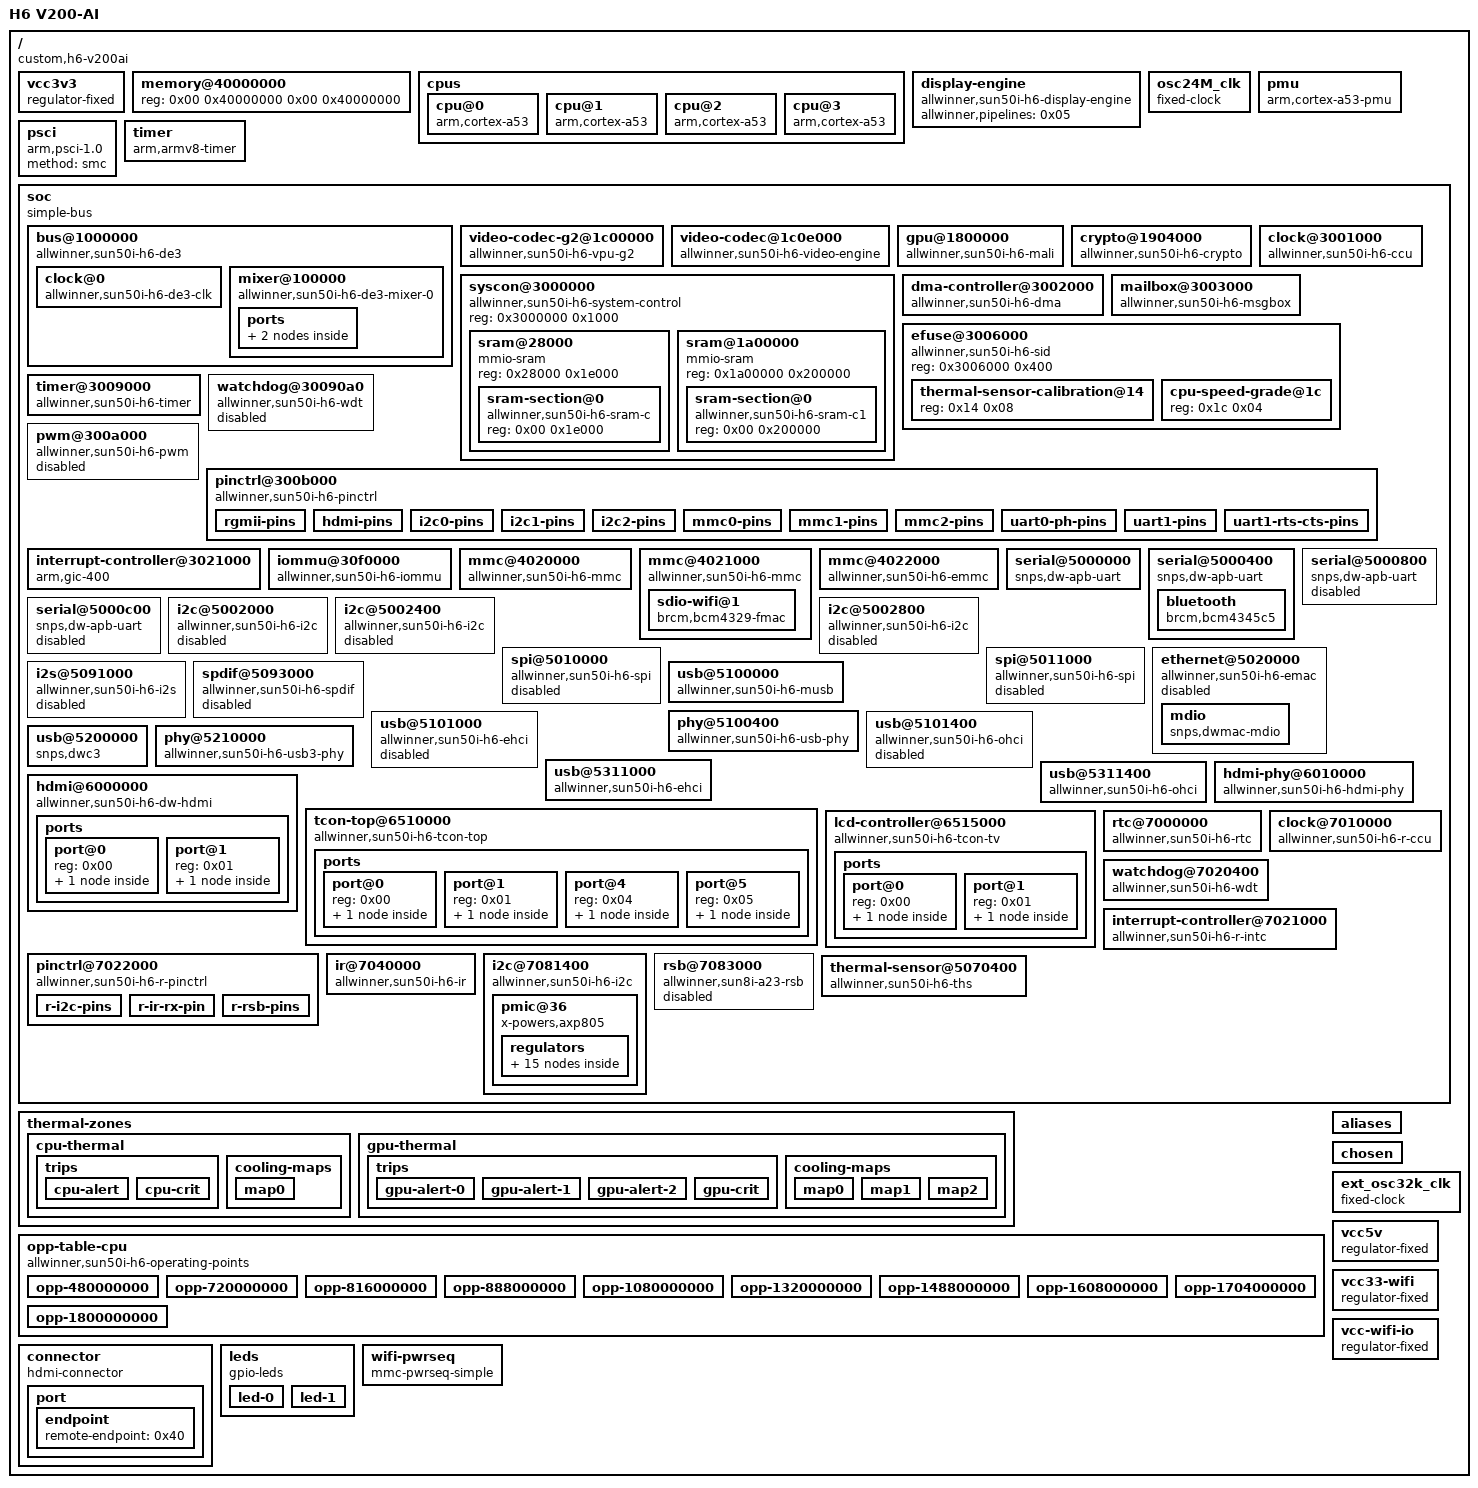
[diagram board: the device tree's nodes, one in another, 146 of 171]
/dts-v1/;

/ {
	interrupt-parent = <0x01>;
	#address-cells = <0x01>;
	#size-cells = <0x01>;
	model = "H6 V200-AI";
	compatible = "custom,h6-v200ai", "allwinner,sun50i-h6";

	vcc3v3 {
		compatible = "regulator-fixed";
		regulator-name = "vcc-3v3";
		regulator-min-microvolt = <0x325aa0>;
		regulator-max-microvolt = <0x325aa0>;
		regulator-always-on;
		phandle = <0x99>;
	};

	memory@40000000 {
		device_type = "memory";
		reg = <0x00 0x40000000 0x00 0x40000000>;
	};

	cpus {
		#address-cells = <0x01>;
		#size-cells = <0x00>;

		cpu@0 {
			compatible = "arm,cortex-a53";
			device_type = "cpu";
			reg = <0x00>;
			enable-method = "psci";
			clocks = <0x02 0x15>;
			clock-latency-ns = <0x3b9b0>;
			#cooling-cells = <0x02>;
			operating-points-v2 = <0x03>;
			cpu-supply = <0x04>;
			phandle = <0x06>;
		};

		cpu@1 {
			compatible = "arm,cortex-a53";
			device_type = "cpu";
			reg = <0x01>;
			enable-method = "psci";
			clocks = <0x02 0x15>;
			clock-latency-ns = <0x3b9b0>;
			#cooling-cells = <0x02>;
			operating-points-v2 = <0x03>;
			phandle = <0x07>;
		};

		cpu@2 {
			compatible = "arm,cortex-a53";
			device_type = "cpu";
			reg = <0x02>;
			enable-method = "psci";
			clocks = <0x02 0x15>;
			clock-latency-ns = <0x3b9b0>;
			#cooling-cells = <0x02>;
			operating-points-v2 = <0x03>;
			phandle = <0x08>;
		};

		cpu@3 {
			compatible = "arm,cortex-a53";
			device_type = "cpu";
			reg = <0x03>;
			enable-method = "psci";
			clocks = <0x02 0x15>;
			clock-latency-ns = <0x3b9b0>;
			#cooling-cells = <0x02>;
			operating-points-v2 = <0x03>;
			phandle = <0x09>;
		};
	};

	display-engine {
		compatible = "allwinner,sun50i-h6-display-engine";
		allwinner,pipelines = <0x05>;
		status = "okay";
	};

	osc24M_clk {
		#clock-cells = <0x00>;
		compatible = "fixed-clock";
		clock-frequency = <0x16e3600>;
		clock-output-names = "osc24M";
		phandle = <0x10>;
	};

	pmu {
		compatible = "arm,cortex-a53-pmu";
		interrupts = <0x00 0x8c 0x04 0x00 0x8d 0x04 0x00 0x8e 0x04 0x00 0x8f 0x04>;
		interrupt-affinity = <0x06 0x07 0x08 0x09>;
	};

	psci {
		compatible = "arm,psci-1.0";
		method = "smc";
	};

	timer {
		compatible = "arm,armv8-timer";
		arm,no-tick-in-suspend;
		interrupts = <0x01 0x0d 0xf04 0x01 0x0e 0xf04 0x01 0x0b 0xf04 0x01 0x0a 0xf04>;
	};

	soc {
		compatible = "simple-bus";
		#address-cells = <0x01>;
		#size-cells = <0x01>;
		ranges;

		bus@1000000 {
			compatible = "allwinner,sun50i-h6-de3", "allwinner,sun50i-a64-de2";
			reg = <0x1000000 0x400000>;
			allwinner,sram = <0x0a 0x01>;
			#address-cells = <0x01>;
			#size-cells = <0x01>;
			ranges = <0x00 0x1000000 0x400000>;

			clock@0 {
				compatible = "allwinner,sun50i-h6-de3-clk";
				reg = <0x00 0x10000>;
				clocks = <0x02 0x1e 0x02 0x1d>;
				clock-names = "bus", "mod";
				resets = <0x02 0x01>;
				#clock-cells = <0x01>;
				#reset-cells = <0x01>;
				phandle = <0x0b>;
			};

			mixer@100000 {
				compatible = "allwinner,sun50i-h6-de3-mixer-0";
				reg = <0x100000 0x100000>;
				clocks = <0x0b 0x00 0x0b 0x06>;
				clock-names = "bus", "mod";
				resets = <0x0b 0x00>;
				iommus = <0x0c 0x00>;
				phandle = <0x05>;

				ports {
					#address-cells = <0x01>;
					#size-cells = <0x00>;

					port@1 {
						reg = <0x01>;

						endpoint {
							remote-endpoint = <0x0d>;
							phandle = <0x2c>;
						};
					};
				};
			};
		};

		video-codec-g2@1c00000 {
			compatible = "allwinner,sun50i-h6-vpu-g2";
			reg = <0x1c00000 0x1000>;
			interrupts = <0x00 0x5a 0x04>;
			clocks = <0x02 0x2a 0x02 0x29>;
			clock-names = "bus", "mod";
			resets = <0x02 0x07>;
			iommus = <0x0c 0x05>;
		};

		video-codec@1c0e000 {
			compatible = "allwinner,sun50i-h6-video-engine";
			reg = <0x1c0e000 0x2000>;
			clocks = <0x02 0x26 0x02 0x25 0x02 0x36>;
			clock-names = "ahb", "mod", "ram";
			resets = <0x02 0x05>;
			interrupts = <0x00 0x59 0x04>;
			allwinner,sram = <0x0e 0x01>;
			iommus = <0x0c 0x03>;
		};

		gpu@1800000 {
			compatible = "allwinner,sun50i-h6-mali", "arm,mali-t720";
			reg = <0x1800000 0x4000>;
			interrupts = <0x00 0x54 0x04 0x00 0x55 0x04 0x00 0x53 0x04>;
			interrupt-names = "job", "mmu", "gpu";
			clocks = <0x02 0x21 0x02 0x22>;
			clock-names = "core", "bus";
			resets = <0x02 0x03>;
			#cooling-cells = <0x02>;
			status = "okay";
			mali-supply = <0x0f>;
			phandle = <0x3c>;
		};

		crypto@1904000 {
			compatible = "allwinner,sun50i-h6-crypto";
			reg = <0x1904000 0x1000>;
			interrupts = <0x00 0x57 0x04>;
			clocks = <0x02 0x24 0x02 0x23 0x02 0x37>;
			clock-names = "bus", "mod", "ram";
			resets = <0x02 0x04>;
		};

		syscon@3000000 {
			compatible = "allwinner,sun50i-h6-system-control", "allwinner,sun50i-a64-system-control";
			reg = <0x3000000 0x1000>;
			#address-cells = <0x01>;
			#size-cells = <0x01>;
			ranges;
			phandle = <0x24>;

			sram@28000 {
				compatible = "mmio-sram";
				reg = <0x28000 0x1e000>;
				#address-cells = <0x01>;
				#size-cells = <0x01>;
				ranges = <0x00 0x28000 0x1e000>;

				sram-section@0 {
					compatible = "allwinner,sun50i-h6-sram-c", "allwinner,sun50i-a64-sram-c";
					reg = <0x00 0x1e000>;
					phandle = <0x0a>;
				};
			};

			sram@1a00000 {
				compatible = "mmio-sram";
				reg = <0x1a00000 0x200000>;
				#address-cells = <0x01>;
				#size-cells = <0x01>;
				ranges = <0x00 0x1a00000 0x200000>;

				sram-section@0 {
					compatible = "allwinner,sun50i-h6-sram-c1", "allwinner,sun4i-a10-sram-c1";
					reg = <0x00 0x200000>;
					phandle = <0x0e>;
				};
			};
		};

		clock@3001000 {
			compatible = "allwinner,sun50i-h6-ccu";
			reg = <0x3001000 0x1000>;
			clocks = <0x10 0x11 0x00 0x11 0x02>;
			clock-names = "hosc", "losc", "iosc";
			#clock-cells = <0x01>;
			#reset-cells = <0x01>;
			phandle = <0x02>;
		};

		dma-controller@3002000 {
			compatible = "allwinner,sun50i-h6-dma";
			reg = <0x3002000 0x1000>;
			interrupts = <0x00 0x2b 0x04>;
			clocks = <0x02 0x2b 0x02 0x35>;
			clock-names = "bus", "mbus";
			dma-channels = <0x10>;
			dma-requests = <0x2e>;
			resets = <0x02 0x08>;
			#dma-cells = <0x01>;
			phandle = <0x23>;
		};

		mailbox@3003000 {
			compatible = "allwinner,sun50i-h6-msgbox", "allwinner,sun6i-a31-msgbox";
			reg = <0x3003000 0x1000>;
			clocks = <0x02 0x2c>;
			resets = <0x02 0x09>;
			interrupts = <0x00 0x2c 0x04>;
			#mbox-cells = <0x01>;
		};

		efuse@3006000 {
			compatible = "allwinner,sun50i-h6-sid";
			reg = <0x3006000 0x400>;
			#address-cells = <0x01>;
			#size-cells = <0x01>;

			thermal-sensor-calibration@14 {
				reg = <0x14 0x08>;
				phandle = <0x38>;
			};

			cpu-speed-grade@1c {
				reg = <0x1c 0x04>;
				phandle = <0x3f>;
			};
		};

		timer@3009000 {
			compatible = "allwinner,sun50i-h6-timer", "allwinner,sun8i-a23-timer";
			reg = <0x3009000 0xa0>;
			interrupts = <0x00 0x30 0x04 0x00 0x31 0x04>;
			clocks = <0x10>;
		};

		watchdog@30090a0 {
			compatible = "allwinner,sun50i-h6-wdt", "allwinner,sun6i-a31-wdt";
			reg = <0x30090a0 0x20>;
			interrupts = <0x00 0x32 0x04>;
			clocks = <0x10>;
			status = "disabled";
		};

		pwm@300a000 {
			compatible = "allwinner,sun50i-h6-pwm";
			reg = <0x300a000 0x400>;
			clocks = <0x10 0x02 0x32>;
			clock-names = "mod", "bus";
			resets = <0x02 0x0e>;
			#pwm-cells = <0x03>;
			status = "disabled";
		};

		pinctrl@300b000 {
			compatible = "allwinner,sun50i-h6-pinctrl";
			reg = <0x300b000 0x400>;
			interrupt-parent = <0x12>;
			interrupts = <0x00 0x33 0x04 0x00 0x35 0x04 0x00 0x36 0x04 0x00 0x3b 0x04>;
			clocks = <0x02 0x1a 0x10 0x11 0x00>;
			clock-names = "apb", "hosc", "losc";
			gpio-controller;
			#gpio-cells = <0x03>;
			interrupt-controller;
			#interrupt-cells = <0x03>;
			phandle = <0x17>;

			rgmii-pins {
				pins = "PD0", "PD1", "PD2", "PD3", "PD4", "PD5", "PD7", "PD8", "PD9", "PD10", "PD11", "PD12", "PD13", "PD19", "PD20";
				function = "emac";
				drive-strength = <0x28>;
			};

			hdmi-pins {
				pins = "PH8", "PH9", "PH10";
				function = "hdmi";
				phandle = <0x29>;
			};

			i2c0-pins {
				pins = "PD25", "PD26";
				function = "i2c0";
				phandle = <0x20>;
			};

			i2c1-pins {
				pins = "PH5", "PH6";
				function = "i2c1";
				phandle = <0x21>;
			};

			i2c2-pins {
				pins = "PD23", "PD24";
				function = "i2c2";
				phandle = <0x22>;
			};

			mmc0-pins {
				pins = "PF0", "PF1", "PF2", "PF3", "PF4", "PF5";
				function = "mmc0";
				drive-strength = <0x1e>;
				bias-pull-up;
				phandle = <0x16>;
			};

			mmc1-pins {
				pins = "PG0", "PG1", "PG2", "PG3", "PG4", "PG5";
				function = "mmc1";
				drive-strength = <0x1e>;
				bias-pull-up;
				phandle = <0x18>;
			};

			mmc2-pins {
				pins = "PC1", "PC4", "PC5", "PC6", "PC7", "PC8", "PC9", "PC10", "PC11", "PC12", "PC13", "PC14";
				function = "mmc2";
				drive-strength = <0x1e>;
				bias-pull-up;
				phandle = <0x1c>;
			};

			uart0-ph-pins {
				pins = "PH0", "PH1";
				function = "uart0";
				phandle = <0x1d>;
			};

			uart1-pins {
				pins = "PG6", "PG7";
				function = "uart1";
				phandle = <0x1e>;
			};

			uart1-rts-cts-pins {
				pins = "PG8", "PG9";
				function = "uart1";
				phandle = <0x1f>;
			};
		};

		interrupt-controller@3021000 {
			compatible = "arm,gic-400";
			reg = <0x3021000 0x1000 0x3022000 0x2000 0x3024000 0x2000 0x3026000 0x2000>;
			interrupts = <0x01 0x09 0xf04>;
			interrupt-controller;
			#interrupt-cells = <0x03>;
			phandle = <0x01>;
		};

		iommu@30f0000 {
			compatible = "allwinner,sun50i-h6-iommu";
			reg = <0x30f0000 0x10000>;
			interrupts = <0x00 0x39 0x04>;
			clocks = <0x02 0x33>;
			resets = <0x02 0x0f>;
			#iommu-cells = <0x01>;
			phandle = <0x0c>;
		};

		mmc@4020000 {
			compatible = "allwinner,sun50i-h6-mmc", "allwinner,sun50i-a64-mmc";
			reg = <0x4020000 0x1000>;
			clocks = <0x02 0x43 0x02 0x40>;
			clock-names = "ahb", "mmc";
			resets = <0x02 0x12>;
			reset-names = "ahb";
			interrupts = <0x00 0x23 0x04>;
			pinctrl-names = "default";
			pinctrl-0 = <0x16>;
			max-frequency = <0x8f0d180>;
			status = "okay";
			#address-cells = <0x01>;
			#size-cells = <0x00>;
			vmmc-supply = <0x14>;
			cd-gpios = <0x17 0x05 0x06 0x01>;
			bus-width = <0x04>;
		};

		mmc@4021000 {
			compatible = "allwinner,sun50i-h6-mmc", "allwinner,sun50i-a64-mmc";
			reg = <0x4021000 0x1000>;
			clocks = <0x02 0x44 0x02 0x41>;
			clock-names = "ahb", "mmc";
			resets = <0x02 0x13>;
			reset-names = "ahb";
			interrupts = <0x00 0x24 0x04>;
			pinctrl-names = "default";
			pinctrl-0 = <0x18>;
			max-frequency = <0x2faf080>;
			status = "okay";
			#address-cells = <0x01>;
			#size-cells = <0x00>;
			vmmc-supply = <0x19>;
			vqmmc-supply = <0x15>;
			mmc-pwrseq = <0x1a>;
			bus-width = <0x04>;
			non-removable;

			sdio-wifi@1 {
				reg = <0x01>;
				compatible = "brcm,bcm4329-fmac";
				interrupt-parent = <0x1b>;
				interrupts = <0x01 0x00 0x08>;
				interrupt-names = "host-wake";
			};
		};

		mmc@4022000 {
			compatible = "allwinner,sun50i-h6-emmc", "allwinner,sun50i-a64-emmc";
			reg = <0x4022000 0x1000>;
			clocks = <0x02 0x45 0x02 0x42>;
			clock-names = "ahb", "mmc";
			resets = <0x02 0x14>;
			reset-names = "ahb";
			interrupts = <0x00 0x25 0x04>;
			pinctrl-names = "default";
			pinctrl-0 = <0x1c>;
			max-frequency = <0x3197500>;
			vmmc-supply = <0x99>;
			status = "okay";
			#address-cells = <0x01>;
			#size-cells = <0x00>;
			non-removable;
			bus-width = <0x08>;
		};

		serial@5000000 {
			compatible = "snps,dw-apb-uart";
			reg = <0x5000000 0x400>;
			interrupts = <0x00 0x00 0x04>;
			reg-shift = <0x02>;
			reg-io-width = <0x04>;
			clocks = <0x02 0x46>;
			resets = <0x02 0x15>;
			status = "okay";
			pinctrl-names = "default";
			pinctrl-0 = <0x1d>;
		};

		serial@5000400 {
			compatible = "snps,dw-apb-uart";
			reg = <0x5000400 0x400>;
			interrupts = <0x00 0x01 0x04>;
			reg-shift = <0x02>;
			reg-io-width = <0x04>;
			clocks = <0x02 0x47>;
			resets = <0x02 0x16>;
			status = "okay";
			pinctrl-names = "default";
			pinctrl-0 = <0x1e 0x1f>;
			uart-has-rtscts;

			bluetooth {
				compatible = "brcm,bcm4345c5";
				clocks = <0x11 0x01>;
				clock-names = "lpo";
				device-wakeup-gpios = <0x1b 0x01 0x02 0x00>;
				host-wakeup-gpios = <0x1b 0x01 0x01 0x00>;
				shutdown-gpios = <0x1b 0x01 0x04 0x00>;
				max-speed = <0x1c200>;
			};
		};

		serial@5000800 {
			compatible = "snps,dw-apb-uart";
			reg = <0x5000800 0x400>;
			interrupts = <0x00 0x02 0x04>;
			reg-shift = <0x02>;
			reg-io-width = <0x04>;
			clocks = <0x02 0x48>;
			resets = <0x02 0x17>;
			status = "disabled";
		};

		serial@5000c00 {
			compatible = "snps,dw-apb-uart";
			reg = <0x5000c00 0x400>;
			interrupts = <0x00 0x03 0x04>;
			reg-shift = <0x02>;
			reg-io-width = <0x04>;
			clocks = <0x02 0x49>;
			resets = <0x02 0x18>;
			status = "disabled";
		};

		i2c@5002000 {
			compatible = "allwinner,sun50i-h6-i2c", "allwinner,sun6i-a31-i2c";
			reg = <0x5002000 0x400>;
			interrupts = <0x00 0x04 0x04>;
			clocks = <0x02 0x4a>;
			resets = <0x02 0x19>;
			pinctrl-names = "default";
			pinctrl-0 = <0x20>;
			status = "disabled";
			#address-cells = <0x01>;
			#size-cells = <0x00>;
		};

		i2c@5002400 {
			compatible = "allwinner,sun50i-h6-i2c", "allwinner,sun6i-a31-i2c";
			reg = <0x5002400 0x400>;
			interrupts = <0x00 0x05 0x04>;
			clocks = <0x02 0x4b>;
			resets = <0x02 0x1a>;
			pinctrl-names = "default";
			pinctrl-0 = <0x21>;
			status = "disabled";
			#address-cells = <0x01>;
			#size-cells = <0x00>;
		};

		i2c@5002800 {
			compatible = "allwinner,sun50i-h6-i2c", "allwinner,sun6i-a31-i2c";
			reg = <0x5002800 0x400>;
			interrupts = <0x00 0x06 0x04>;
			clocks = <0x02 0x4c>;
			resets = <0x02 0x1b>;
			pinctrl-names = "default";
			pinctrl-0 = <0x22>;
			status = "disabled";
			#address-cells = <0x01>;
			#size-cells = <0x00>;
		};

		spi@5010000 {
			compatible = "allwinner,sun50i-h6-spi", "allwinner,sun8i-h3-spi";
			reg = <0x5010000 0x1000>;
			interrupts = <0x00 0x0a 0x04>;
			clocks = <0x02 0x52 0x02 0x50>;
			clock-names = "ahb", "mod";
			dmas = <0x23 0x16 0x23 0x16>;
			dma-names = "rx", "tx";
			resets = <0x02 0x1f>;
			status = "disabled";
			#address-cells = <0x01>;
			#size-cells = <0x00>;
		};

		spi@5011000 {
			compatible = "allwinner,sun50i-h6-spi", "allwinner,sun8i-h3-spi";
			reg = <0x5011000 0x1000>;
			interrupts = <0x00 0x0b 0x04>;
			clocks = <0x02 0x53 0x02 0x51>;
			clock-names = "ahb", "mod";
			dmas = <0x23 0x17 0x23 0x17>;
			dma-names = "rx", "tx";
			resets = <0x02 0x20>;
			status = "disabled";
			#address-cells = <0x01>;
			#size-cells = <0x00>;
		};

		ethernet@5020000 {
			compatible = "allwinner,sun50i-h6-emac", "allwinner,sun50i-a64-emac";
			syscon = <0x24>;
			reg = <0x5020000 0x10000>;
			interrupts = <0x00 0x0c 0x04>;
			interrupt-names = "macirq";
			resets = <0x02 0x21>;
			reset-names = "stmmaceth";
			clocks = <0x02 0x54>;
			clock-names = "stmmaceth";
			status = "disabled";

			mdio {
				compatible = "snps,dwmac-mdio";
				#address-cells = <0x01>;
				#size-cells = <0x00>;
			};
		};

		i2s@5091000 {
			#sound-dai-cells = <0x00>;
			compatible = "allwinner,sun50i-h6-i2s";
			reg = <0x5091000 0x1000>;
			interrupts = <0x00 0x13 0x04>;
			clocks = <0x02 0x5f 0x02 0x5c>;
			clock-names = "apb", "mod";
			dmas = <0x23 0x04 0x23 0x04>;
			resets = <0x02 0x26>;
			dma-names = "rx", "tx";
			status = "disabled";
		};

		spdif@5093000 {
			#sound-dai-cells = <0x00>;
			compatible = "allwinner,sun50i-h6-spdif";
			reg = <0x5093000 0x400>;
			interrupts = <0x00 0x15 0x04>;
			clocks = <0x02 0x63 0x02 0x62>;
			clock-names = "apb", "spdif";
			resets = <0x02 0x29>;
			dmas = <0x23 0x02 0x23 0x02>;
			dma-names = "rx", "tx";
			status = "disabled";
		};

		usb@5100000 {
			compatible = "allwinner,sun50i-h6-musb", "allwinner,sun8i-a33-musb";
			reg = <0x5100000 0x400>;
			clocks = <0x02 0x74>;
			resets = <0x02 0x35>;
			interrupts = <0x00 0x17 0x04>;
			interrupt-names = "mc";
			phys = <0x25 0x00>;
			phy-names = "usb";
			extcon = <0x25 0x00>;
			status = "okay";
			dr_mode = "peripheral";
		};

		phy@5100400 {
			compatible = "allwinner,sun50i-h6-usb-phy";
			reg = <0x5100400 0x24 0x5101800 0x04 0x5311800 0x04>;
			reg-names = "phy_ctrl", "pmu0", "pmu3";
			clocks = <0x02 0x69 0x02 0x6c>;
			clock-names = "usb0_phy", "usb3_phy";
			resets = <0x02 0x2c 0x02 0x2e>;
			reset-names = "usb0_reset", "usb3_reset";
			status = "okay";
			#phy-cells = <0x01>;
			usb0_vbus-supply = <0x26>;
			usb3_vbus-supply = <0x26>;
			phandle = <0x25>;
		};

		usb@5101000 {
			compatible = "allwinner,sun50i-h6-ehci", "generic-ehci";
			reg = <0x5101000 0x100>;
			interrupts = <0x00 0x18 0x04>;
			clocks = <0x02 0x6f 0x02 0x71 0x02 0x68>;
			resets = <0x02 0x30 0x02 0x32>;
			phys = <0x25 0x00>;
			phy-names = "usb";
			status = "disabled";
		};

		usb@5101400 {
			compatible = "allwinner,sun50i-h6-ohci", "generic-ohci";
			reg = <0x5101400 0x100>;
			interrupts = <0x00 0x19 0x04>;
			clocks = <0x02 0x6f 0x02 0x68>;
			resets = <0x02 0x30>;
			phys = <0x25 0x00>;
			phy-names = "usb";
			status = "disabled";
		};

		usb@5200000 {
			compatible = "snps,dwc3";
			reg = <0x5200000 0x10000>;
			interrupts = <0x00 0x1a 0x04>;
			clocks = <0x02 0x72 0x02 0x72 0x11 0x00>;
			clock-names = "ref", "bus_early", "suspend";
			resets = <0x02 0x33>;
			dr_mode = "host";
			phys = <0x27>;
			phy-names = "usb3-phy";
			status = "okay";
		};

		phy@5210000 {
			compatible = "allwinner,sun50i-h6-usb3-phy";
			reg = <0x5210000 0x10000>;
			clocks = <0x02 0x6a>;
			resets = <0x02 0x2d>;
			#phy-cells = <0x00>;
			status = "okay";
			phandle = <0x27>;
		};

		usb@5311000 {
			compatible = "allwinner,sun50i-h6-ehci", "generic-ehci";
			reg = <0x5311000 0x100>;
			interrupts = <0x00 0x1c 0x04>;
			clocks = <0x02 0x70 0x02 0x73 0x02 0x6b>;
			resets = <0x02 0x31 0x02 0x34>;
			phys = <0x25 0x03>;
			phy-names = "usb";
			status = "okay";
		};

		usb@5311400 {
			compatible = "allwinner,sun50i-h6-ohci", "generic-ohci";
			reg = <0x5311400 0x100>;
			interrupts = <0x00 0x1d 0x04>;
			clocks = <0x02 0x70 0x02 0x6b>;
			resets = <0x02 0x31>;
			phys = <0x25 0x03>;
			phy-names = "usb";
			status = "okay";
		};

		hdmi@6000000 {
			compatible = "allwinner,sun50i-h6-dw-hdmi";
			reg = <0x6000000 0x10000>;
			reg-io-width = <0x01>;
			interrupts = <0x00 0x40 0x04>;
			clocks = <0x02 0x7e 0x02 0x7c 0x02 0x7b 0x02 0x7d 0x02 0x88 0x02 0x89>;
			clock-names = "iahb", "isfr", "tmds", "cec", "hdcp", "hdcp-bus";
			resets = <0x02 0x39 0x02 0x3e>;
			reset-names = "ctrl", "hdcp";
			phys = <0x28>;
			phy-names = "phy";
			pinctrl-names = "default";
			pinctrl-0 = <0x29>;
			status = "okay";

			ports {
				#address-cells = <0x01>;
				#size-cells = <0x00>;

				port@0 {
					reg = <0x00>;

					endpoint {
						remote-endpoint = <0x2a>;
						phandle = <0x2f>;
					};
				};

				port@1 {
					reg = <0x01>;

					endpoint {
						remote-endpoint = <0x2b>;
						phandle = <0x40>;
					};
				};
			};
		};

		hdmi-phy@6010000 {
			compatible = "allwinner,sun50i-h6-hdmi-phy";
			reg = <0x6010000 0x10000>;
			clocks = <0x02 0x7e 0x02 0x7c>;
			clock-names = "bus", "mod";
			resets = <0x02 0x38>;
			reset-names = "phy";
			#phy-cells = <0x00>;
			phandle = <0x28>;
		};

		tcon-top@6510000 {
			compatible = "allwinner,sun50i-h6-tcon-top";
			reg = <0x6510000 0x1000>;
			clocks = <0x02 0x7f 0x02 0x82>;
			clock-names = "bus", "tcon-tv0";
			clock-output-names = "tcon-top-tv0";
			resets = <0x02 0x3a>;
			#clock-cells = <0x01>;
			phandle = <0x30>;

			ports {
				#address-cells = <0x01>;
				#size-cells = <0x00>;

				port@0 {
					#address-cells = <0x01>;
					#size-cells = <0x00>;
					reg = <0x00>;

					endpoint@0 {
						reg = <0x00>;
						remote-endpoint = <0x2c>;
						phandle = <0x0d>;
					};
				};

				port@1 {
					#address-cells = <0x01>;
					#size-cells = <0x00>;
					reg = <0x01>;

					endpoint@2 {
						reg = <0x02>;
						remote-endpoint = <0x2d>;
						phandle = <0x31>;
					};
				};

				port@4 {
					#address-cells = <0x01>;
					#size-cells = <0x00>;
					reg = <0x04>;

					endpoint@0 {
						reg = <0x00>;
						remote-endpoint = <0x2e>;
						phandle = <0x32>;
					};
				};

				port@5 {
					reg = <0x05>;

					endpoint {
						remote-endpoint = <0x2f>;
						phandle = <0x2a>;
					};
				};
			};
		};

		lcd-controller@6515000 {
			compatible = "allwinner,sun50i-h6-tcon-tv", "allwinner,sun8i-r40-tcon-tv";
			reg = <0x6515000 0x1000>;
			interrupts = <0x00 0x42 0x04>;
			clocks = <0x02 0x83 0x30 0x00>;
			clock-names = "ahb", "tcon-ch1";
			resets = <0x02 0x3c>;
			reset-names = "lcd";

			ports {
				#address-cells = <0x01>;
				#size-cells = <0x00>;

				port@0 {
					reg = <0x00>;

					endpoint {
						remote-endpoint = <0x31>;
						phandle = <0x2d>;
					};
				};

				port@1 {
					#address-cells = <0x01>;
					#size-cells = <0x00>;
					reg = <0x01>;

					endpoint@1 {
						reg = <0x01>;
						remote-endpoint = <0x32>;
						phandle = <0x2e>;
					};
				};
			};
		};

		rtc@7000000 {
			compatible = "allwinner,sun50i-h6-rtc";
			reg = <0x7000000 0x400>;
			interrupt-parent = <0x12>;
			interrupts = <0x00 0x65 0x04 0x00 0x66 0x04>;
			clock-output-names = "osc32k", "osc32k-out", "iosc";
			#clock-cells = <0x01>;
			clocks = <0x33>;
			phandle = <0x11>;
		};

		clock@7010000 {
			compatible = "allwinner,sun50i-h6-r-ccu";
			reg = <0x7010000 0x400>;
			clocks = <0x10 0x11 0x00 0x11 0x02 0x02 0x03>;
			clock-names = "hosc", "losc", "iosc", "pll-periph";
			#clock-cells = <0x01>;
			#reset-cells = <0x01>;
			phandle = <0x34>;
		};

		watchdog@7020400 {
			compatible = "allwinner,sun50i-h6-wdt", "allwinner,sun6i-a31-wdt";
			reg = <0x7020400 0x20>;
			interrupts = <0x00 0x67 0x04>;
			clocks = <0x10>;
		};

		interrupt-controller@7021000 {
			compatible = "allwinner,sun50i-h6-r-intc";
			interrupt-controller;
			#interrupt-cells = <0x03>;
			reg = <0x7021000 0x400>;
			interrupts = <0x00 0x60 0x04>;
			phandle = <0x12>;
		};

		pinctrl@7022000 {
			compatible = "allwinner,sun50i-h6-r-pinctrl";
			reg = <0x7022000 0x400>;
			interrupt-parent = <0x12>;
			interrupts = <0x00 0x69 0x04 0x00 0x6f 0x04>;
			clocks = <0x34 0x02 0x10 0x11 0x00>;
			clock-names = "apb", "hosc", "losc";
			gpio-controller;
			#gpio-cells = <0x03>;
			interrupt-controller;
			#interrupt-cells = <0x03>;
			phandle = <0x1b>;

			r-i2c-pins {
				pins = "PL0", "PL1";
				function = "s_i2c";
				phandle = <0x36>;
			};

			r-ir-rx-pin {
				pins = "PL9";
				function = "s_cir_rx";
				phandle = <0x35>;
			};

			r-rsb-pins {
				pins = "PL0", "PL1";
				function = "s_rsb";
				phandle = <0x37>;
			};
		};

		ir@7040000 {
			compatible = "allwinner,sun50i-h6-ir", "allwinner,sun6i-a31-ir";
			reg = <0x7040000 0x400>;
			interrupts = <0x00 0x6d 0x04>;
			clocks = <0x34 0x09 0x34 0x0b>;
			clock-names = "apb", "ir";
			resets = <0x34 0x05>;
			pinctrl-names = "default";
			pinctrl-0 = <0x35>;
			status = "okay";
		};

		i2c@7081400 {
			compatible = "allwinner,sun50i-h6-i2c", "allwinner,sun6i-a31-i2c";
			reg = <0x7081400 0x400>;
			interrupts = <0x00 0x6b 0x04>;
			clocks = <0x34 0x08>;
			resets = <0x34 0x04>;
			pinctrl-names = "default";
			pinctrl-0 = <0x36>;
			status = "okay";
			#address-cells = <0x01>;
			#size-cells = <0x00>;

			pmic@36 {
				compatible = "x-powers,axp805", "x-powers,axp806";
				reg = <0x36>;
				interrupt-parent = <0x12>;
				interrupts = <0x00 0x60 0x08>;
				interrupt-controller;
				#interrupt-cells = <0x01>;
				x-powers,self-working-mode;
				vina-supply = <0x26>;
				vinb-supply = <0x26>;
				vinc-supply = <0x26>;
				vind-supply = <0x26>;
				vine-supply = <0x26>;
				aldoin-supply = <0x26>;
				bldoin-supply = <0x26>;
				cldoin-supply = <0x26>;

				regulators {

					aldo1 {
						regulator-always-on;
						regulator-min-microvolt = <0x325aa0>;
						regulator-max-microvolt = <0x325aa0>;
						regulator-name = "vcc-pl-led-ir";
					};

					aldo2 {
						regulator-min-microvolt = <0x325aa0>;
						regulator-max-microvolt = <0x325aa0>;
						regulator-name = "vcc33-audio-tv-ephy-mac";
					};

					aldo3 {
						regulator-always-on;
						regulator-min-microvolt = <0x325aa0>;
						regulator-max-microvolt = <0x325aa0>;
						regulator-name = "vcc33-io-pd-emmc-sd-usb-uart-1";
					};

					bldo1 {
						regulator-always-on;
						regulator-min-microvolt = <0x1b7740>;
						regulator-max-microvolt = <0x1b7740>;
						regulator-name = "vcc18-dram-bias-pll";
					};

					bldo2 {
						regulator-always-on;
						regulator-min-microvolt = <0x1b7740>;
						regulator-max-microvolt = <0x1b7740>;
						regulator-name = "vcc-efuse-pcie-hdmi-pc";
						phandle = <0x13>;
					};

					bldo3 {
					};

					bldo4 {
					};

					cldo1 {
						regulator-always-on;
						regulator-min-microvolt = <0x325aa0>;
						regulator-max-microvolt = <0x325aa0>;
						regulator-name = "vcc33-io-pd-emmc-sd-usb-uart-2";
						phandle = <0x14>;
					};

					cldo2 {
					};

					cldo3 {
					};

					dcdca {
						regulator-always-on;
						regulator-min-microvolt = "", "\f5";
						regulator-max-microvolt = <0x11b340>;
						regulator-ramp-delay = <0x9c4>;
						regulator-name = "vdd-cpu";
						phandle = <0x04>;
					};

					dcdcc {
						regulator-enable-ramp-delay = <0x7d00>;
						regulator-min-microvolt = <0xc5c10>;
						regulator-max-microvolt = <0x107ac0>;
						regulator-ramp-delay = <0x9c4>;
						regulator-name = "vdd-gpu";
						phandle = <0x0f>;
					};

					dcdcd {
						regulator-always-on;
						regulator-min-microvolt = <0xea600>;
						regulator-max-microvolt = <0xea600>;
						regulator-name = "vdd-sys";
					};

					dcdce {
						regulator-always-on;
						regulator-min-microvolt = <0x124f80>;
						regulator-max-microvolt = <0x124f80>;
						regulator-name = "vcc-dram";
					};

					sw {
					};
				};
			};
		};

		rsb@7083000 {
			compatible = "allwinner,sun8i-a23-rsb";
			reg = <0x7083000 0x400>;
			interrupts = <0x00 0x6c 0x04>;
			clocks = <0x34 0x0d>;
			clock-frequency = <0x2dc6c0>;
			resets = <0x34 0x07>;
			pinctrl-names = "default";
			pinctrl-0 = <0x37>;
			status = "disabled";
			#address-cells = <0x01>;
			#size-cells = <0x00>;
		};

		thermal-sensor@5070400 {
			compatible = "allwinner,sun50i-h6-ths";
			reg = <0x5070400 0x100>;
			interrupts = <0x00 0x0f 0x04>;
			clocks = <0x02 0x59>;
			clock-names = "bus";
			resets = <0x02 0x24>;
			nvmem-cells = <0x38>;
			nvmem-cell-names = "calibration";
			#thermal-sensor-cells = <0x01>;
			phandle = <0x39>;
		};
	};

	thermal-zones {

		cpu-thermal {
			polling-delay-passive = <0x00>;
			polling-delay = <0x00>;
			thermal-sensors = <0x39 0x00>;

			trips {

				cpu-alert {
					temperature = <0x14c08>;
					hysteresis = <0x7d0>;
					type = "passive";
					phandle = <0x3a>;
				};

				cpu-crit {
					temperature = <0x186a0>;
					hysteresis = <0x00>;
					type = "critical";
				};
			};

			cooling-maps {

				map0 {
					trip = <0x3a>;
					cooling-device = <0x06 0xffffffff 0xffffffff 0x07 0xffffffff 0xffffffff 0x08 0xffffffff 0xffffffff 0x09 0xffffffff 0xffffffff>;
				};
			};
		};

		gpu-thermal {
			polling-delay-passive = <0x3e8>;
			polling-delay = <0x7d0>;
			thermal-sensors = <0x39 0x01>;

			trips {

				gpu-alert-0 {
					temperature = <0x17318>;
					hysteresis = <0x7d0>;
					type = "passive";
					phandle = <0x3b>;
				};

				gpu-alert-1 {
					temperature = <0x186a0>;
					hysteresis = <0x7d0>;
					type = "passive";
					phandle = <0x3d>;
				};

				gpu-alert-2 {
					temperature = <0x19a28>;
					hysteresis = <0x7d0>;
					type = "passive";
					phandle = <0x3e>;
				};

				gpu-crit {
					temperature = <0x1c138>;
					hysteresis = <0x00>;
					type = "critical";
				};
			};

			cooling-maps {

				map0 {
					trip = <0x3b>;
					cooling-device = <0x3c 0x01 0xffffffff>;
				};

				map1 {
					trip = <0x3d>;
					cooling-device = <0x3c 0x02 0xffffffff>;
				};

				map2 {
					trip = <0x3e>;
					cooling-device = <0x3c 0x03 0xffffffff>;
				};
			};
		};
	};

	opp-table-cpu {
		compatible = "allwinner,sun50i-h6-operating-points";
		nvmem-cells = <0x3f>;
		opp-shared;
		phandle = <0x03>;

		opp-480000000 {
			clock-latency-ns = <0x3b9b0>;
			opp-hz = <0x00 0x1c9c3800>;
			opp-microvolt-speed0 = <0xd6d80 0xd6d80 0x124f80>;
			opp-microvolt-speed1 = <0xc8320 0xc8320 0x124f80>;
			opp-microvolt-speed2 = <0xc8320 0xc8320 0x124f80>;
		};

		opp-720000000 {
			clock-latency-ns = <0x3b9b0>;
			opp-hz = <0x00 0x2aea5400>;
			opp-microvolt-speed0 = <0xd6d80 0xd6d80 0x124f80>;
			opp-microvolt-speed1 = <0xc8320 0xc8320 0x124f80>;
			opp-microvolt-speed2 = <0xc8320 0xc8320 0x124f80>;
		};

		opp-816000000 {
			clock-latency-ns = <0x3b9b0>;
			opp-hz = <0x00 0x30a32c00>;
			opp-microvolt-speed0 = <0xd6d80 0xd6d80 0x124f80>;
			opp-microvolt-speed1 = <0xc8320 0xc8320 0x124f80>;
			opp-microvolt-speed2 = <0xc8320 0xc8320 0x124f80>;
		};

		opp-888000000 {
			clock-latency-ns = <0x3b9b0>;
			opp-hz = <0x00 0x34edce00>;
			opp-microvolt-speed0 = <0xd6d80 0xd6d80 0x124f80>;
			opp-microvolt-speed1 = <0xc8320 0xc8320 0x124f80>;
			opp-microvolt-speed2 = <0xc8320 0xc8320 0x124f80>;
		};

		opp-1080000000 {
			clock-latency-ns = <0x3b9b0>;
			opp-hz = <0x00 0x405f7e00>;
			opp-microvolt-speed0 = <0xe57e0 0xe57e0 0x124f80>;
			opp-microvolt-speed1 = <0xd6d80 0xd6d80 0x124f80>;
			opp-microvolt-speed2 = <0xd6d80 0xd6d80 0x124f80>;
		};

		opp-1320000000 {
			clock-latency-ns = <0x3b9b0>;
			opp-hz = <0x00 0x4ead9a00>;
			opp-microvolt-speed0 = <0xf4240 0xf4240 0x124f80>;
			opp-microvolt-speed1 = <0xe57e0 0xe57e0 0x124f80>;
			opp-microvolt-speed2 = <0xe57e0 0xe57e0 0x124f80>;
		};

		opp-1488000000 {
			clock-latency-ns = <0x3b9b0>;
			opp-hz = <0x00 0x58b11400>;
			opp-microvolt-speed0 = <0x102ca0 0x102ca0 0x124f80>;
			opp-microvolt-speed1 = <0xf4240 0xf4240 0x124f80>;
			opp-microvolt-speed2 = <0xf4240 0xf4240 0x124f80>;
		};

		opp-1608000000 {
			clock-latency-ns = <0x3b9b0>;
			opp-hz = <0x00 0x5fd82200>;
			opp-microvolt-speed0 = <0x10a1d0 0x10a1d0 0x124f80>;
			opp-microvolt-speed1 = <0xfb770 0xfb770 0x124f80>;
			opp-microvolt-speed2 = <0xfb770 0xfb770 0x124f80>;
		};

		opp-1704000000 {
			clock-latency-ns = <0x3b9b0>;
			opp-hz = <0x00 0x6590fa00>;
			opp-microvolt-speed0 = <0x111700 0x111700 0x124f80>;
			opp-microvolt-speed1 = <0x102ca0 0x102ca0 0x124f80>;
			opp-microvolt-speed2 = <0x102ca0 0x102ca0 0x124f80>;
		};

		opp-1800000000 {
			clock-latency-ns = <0x3b9b0>;
			opp-hz = <0x00 0x6b49d200>;
			opp-microvolt-speed0 = <0x11b340 0x11b340 0x124f80>;
			opp-microvolt-speed1 = <0x10c8e0 0x10c8e0 0x124f80>;
			opp-microvolt-speed2 = <0x10c8e0 0x10c8e0 0x124f80>;
		};
	};

	aliases {
		serial0 = "/soc/serial@5000000";
		serial1 = "/soc/serial@5000400";
	};

	chosen {
		stdout-path = "serial0:115200n8";
		bootargs = "console=tty0 loglevel=7 panic=10";
		linux,initrd-start = <0x50000000>;
		linux,initrd-end = <0x5052fdc4>;
	};

	connector {
		compatible = "hdmi-connector";
		ddc-en-gpios = <0x17 0x07 0x02 0x00>;
		type = "a";

		port {

			endpoint {
				remote-endpoint = <0x40>;
				phandle = <0x2b>;
			};
		};
	};

	ext_osc32k_clk {
		#clock-cells = <0x00>;
		compatible = "fixed-clock";
		clock-frequency = <0x8000>;
		clock-output-names = "ext_osc32k";
		phandle = <0x33>;
	};

	leds {
		compatible = "gpio-leds";

		led-0 {
			label = "v200ai:red:power";
			gpios = <0x1b 0x00 0x04 0x00>;
			default-state = "on";
		};

		led-1 {
			label = "v200ai:blue:status";
			gpios = <0x1b 0x00 0x07 0x00>;
		};
	};

	vcc5v {
		compatible = "regulator-fixed";
		regulator-name = "vcc-5v";
		regulator-min-microvolt = <0x4c4b40>;
		regulator-max-microvolt = <0x4c4b40>;
		regulator-always-on;
		phandle = <0x26>;
	};

	vcc33-wifi {
		compatible = "regulator-fixed";
		regulator-name = "vcc33-wifi";
		regulator-min-microvolt = <0x325aa0>;
		regulator-max-microvolt = <0x325aa0>;
		regulator-always-on;
		vin-supply = <0x26>;
		phandle = <0x19>;
	};

	vcc-wifi-io {
		compatible = "regulator-fixed";
		regulator-name = "vcc-wifi-io";
		regulator-min-microvolt = <0x1b7740>;
		regulator-max-microvolt = <0x1b7740>;
		regulator-always-on;
		vin-supply = <0x19>;
		phandle = <0x15>;
	};

	wifi-pwrseq {
		compatible = "mmc-pwrseq-simple";
		clocks = <0x11 0x01>;
		clock-names = "ext_clock";
		reset-gpios = <0x1b 0x01 0x03 0x01>;
		post-power-on-delay-ms = <0xc8>;
		phandle = <0x1a>;
	};
};
